VERSION ""

NS_ :

BS_:

BU_: Sensor adv_logic basic_logic

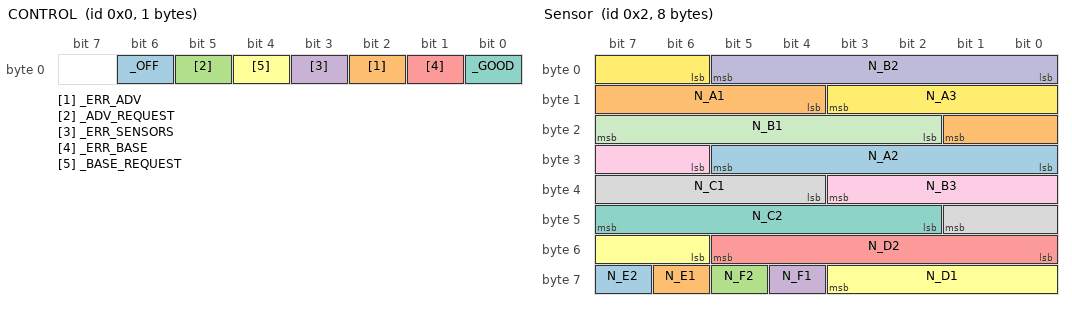
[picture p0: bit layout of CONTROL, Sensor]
BO_ 0 CONTROL: 1 adv_logic
 SG_ _OFF : 6|1@1+ (1,0) [0|0] "" Vector__XXX
 SG_ _ERR_ADV : 2|1@1+ (1,0) [0|0] ""  adv_logic,basic_logic,Sensor
 SG_ _ADV_REQUEST : 5|1@1+ (1,0) [0|0] ""  adv_logic,basic_logic,Sensor
 SG_ _ERR_SENSORS : 3|1@1+ (1,0) [0|0] ""  adv_logic,basic_logic,Sensor
 SG_ _ERR_BASE : 1|1@1+ (1,0) [0|0] ""  adv_logic,basic_logic,Sensor
 SG_ _BASE_REQUEST : 4|1@1+ (1,0) [0|0] ""  adv_logic,basic_logic,Sensor
 SG_ _GOOD : 0|1@1+ (1,0) [0|0] ""  adv_logic,basic_logic,Sensor

BO_ 2 Sensor: 8 Sensor
 SG_ N_E2 : 63|1@1+ (1,0) [0|0] ""  Sensor,adv_logic
 SG_ N_E1 : 62|1@1+ (1,0) [0|0] ""  Sensor,adv_logic
 SG_ N_F2 : 61|1@1+ (1,0) [0|0] ""  Sensor,adv_logic
 SG_ N_F1 : 60|1@1+ (1,0) [0|0] ""  Sensor,adv_logic
 SG_ N_D2 : 48|6@1+ (1,0) [0|0] ""  Sensor,adv_logic
 SG_ N_D1 : 54|6@1+ (1,0) [0|0] ""  Sensor,adv_logic
 SG_ N_C2 : 42|6@1+ (1,0) [0|0] ""  Sensor,adv_logic
 SG_ N_C1 : 36|6@1+ (1,0) [0|0] ""  Sensor,adv_logic
 SG_ N_B3 : 30|6@1+ (1,0) [0|0] ""  Sensor,adv_logic
 SG_ N_B2 : 0|6@1+ (1,0) [0|0] ""  Sensor,adv_logic
 SG_ N_B1 : 18|6@1+ (1,0) [0|0] ""  Sensor,adv_logic
 SG_ N_A3 : 6|6@1+ (1,0) [0|0] ""  Sensor,adv_logic
 SG_ N_A2 : 24|6@1+ (1,0) [0|0] ""  Sensor,adv_logic
 SG_ N_A1 : 12|6@1+ (1,0) [0|0] ""  Sensor,adv_logic

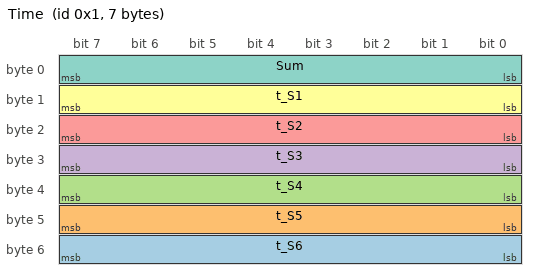
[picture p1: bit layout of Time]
BO_ 1 Time: 7 adv_logic
 SG_ t_S6 : 48|8@1+ (1,0) [0|0] ""  Sensor,basic_logic
 SG_ t_S5 : 40|8@1+ (1,0) [0|0] ""  Sensor,basic_logic
 SG_ t_S4 : 32|8@1+ (1,0) [0|0] ""  Sensor,basic_logic
 SG_ t_S3 : 24|8@1+ (1,0) [0|0] ""  Sensor,basic_logic
 SG_ t_S2 : 16|8@1+ (1,0) [0|0] ""  Sensor,basic_logic
 SG_ t_S1 : 8|8@1+ (1,0) [0|0] ""  Sensor,basic_logic
 SG_ Sum : 0|8@1+ (1,0) [0|0] ""  Sensor,basic_logic

BO_ 3 Display: 5 adv_logic
 SG_ F_R : 33|1@1+ (1,0) [0|0] ""  Sensor,adv_logic,basic_logic
 SG_ F_G : 32|1@1+ (1,0) [0|0] ""  Sensor,adv_logic,basic_logic
 SG_ E_R : 31|1@1+ (1,0) [0|0] ""  Sensor,adv_logic,basic_logic
 SG_ E_G : 30|1@1+ (1,0) [0|0] ""  Sensor,adv_logic,basic_logic
 SG_ D1_Y : 25|1@1+ (1,0) [0|0] ""  Sensor,adv_logic,basic_logic
 SG_ D2_R : 29|1@1+ (1,0) [0|0] ""  Sensor,adv_logic,basic_logic
 SG_ D2_G : 27|1@1+ (1,0) [0|0] ""  Sensor,adv_logic,basic_logic
 SG_ D1_R : 26|1@1+ (1,0) [0|0] ""  Sensor,adv_logic,basic_logic
 SG_ D2_Y : 28|1@1+ (1,0) [0|0] ""  Sensor,adv_logic,basic_logic
 SG_ D1_G : 24|1@1+ (1,0) [0|0] ""  Sensor,adv_logic,basic_logic
 SG_ C2_Y : 22|1@1+ (1,0) [0|0] ""  Sensor,adv_logic,basic_logic
 SG_ C2_R : 23|1@1+ (1,0) [0|0] ""  Sensor,adv_logic,basic_logic
 SG_ C2_G : 21|1@1+ (1,0) [0|0] ""  Sensor,adv_logic,basic_logic
 SG_ C1_R : 20|1@1+ (1,0) [0|0] ""  Sensor,adv_logic,basic_logic
 SG_ C1_Y : 19|1@1+ (1,0) [0|0] ""  Sensor,adv_logic,basic_logic
 SG_ C1_G : 18|1@1+ (1,0) [0|0] ""  Sensor,adv_logic,basic_logic
 SG_ B3_R : 17|1@1+ (1,0) [0|0] ""  Sensor,adv_logic,basic_logic
 SG_ B3_Y : 16|1@1+ (1,0) [0|0] ""  Sensor,adv_logic,basic_logic
 SG_ B3_G : 15|1@1+ (1,0) [0|0] ""  Sensor,adv_logic,basic_logic
 SG_ B2_R : 14|1@1+ (1,0) [0|0] ""  Sensor,adv_logic,basic_logic
 SG_ B2_Y : 13|1@1+ (1,0) [0|0] ""  Sensor,adv_logic,basic_logic
 SG_ B2_G : 12|1@1+ (1,0) [0|0] ""  Sensor,adv_logic,basic_logic
 SG_ B1_R : 11|1@1+ (1,0) [0|0] ""  Sensor,adv_logic,basic_logic
 SG_ B1_Y : 10|1@1+ (1,0) [0|0] ""  Sensor,adv_logic,basic_logic
 SG_ B1_G : 9|1@1+ (1,0) [0|0] ""  Sensor,adv_logic,basic_logic
 SG_ A3_R : 8|1@1+ (1,0) [0|0] ""  Sensor,adv_logic,basic_logic
 SG_ A3_Y : 7|1@1+ (1,0) [0|0] ""  Sensor,adv_logic,basic_logic
 SG_ A3_G : 6|1@1+ (1,0) [0|0] ""  Sensor,adv_logic,basic_logic
 SG_ A2_R : 5|1@1+ (1,0) [0|0] ""  Sensor,adv_logic,basic_logic
 SG_ A2_Y : 4|1@1+ (1,0) [0|0] ""  Sensor,adv_logic,basic_logic
 SG_ A2_G : 3|1@1+ (1,0) [0|0] ""  Sensor,adv_logic,basic_logic
 SG_ A1_R : 2|1@1+ (1,0) [0|0] ""  Sensor,adv_logic,basic_logic
 SG_ A1_Y : 1|1@1+ (1,0) [0|0] ""  Sensor,adv_logic,basic_logic
 SG_ A1_G : 0|1@1+ (1,0) [0|0] ""  Sensor,adv_logic,basic_logic

BO_TX_BU_ 0 : Sensor,basic_logic,adv_logic;
BO_TX_BU_ 3 : basic_logic,adv_logic;

BA_DEF_  "BusType" STRING ;
BA_DEF_DEF_  "BusType" "CAN";
